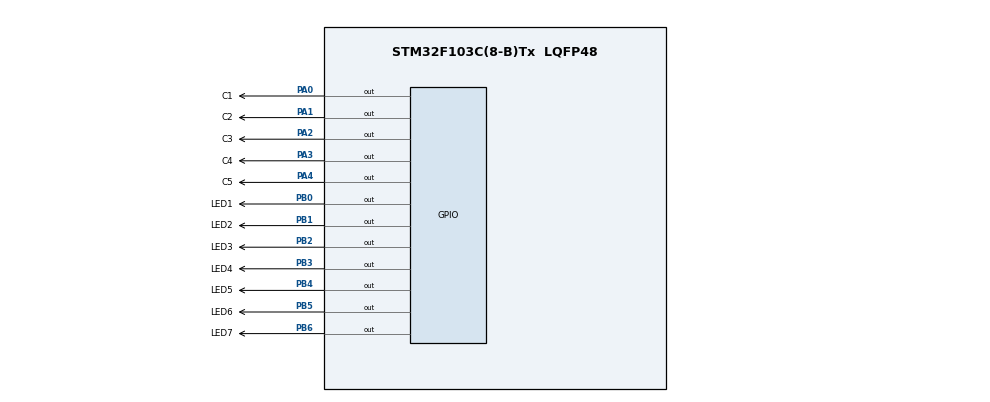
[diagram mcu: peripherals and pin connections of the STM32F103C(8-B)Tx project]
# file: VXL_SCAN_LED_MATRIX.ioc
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Mcu.Family=STM32F1
Mcu.Name=STM32F103C(8-B)Tx
Mcu.Package=LQFP48
NVIC.PriorityGroup=NVIC_PRIORITYGROUP_4
PA0-WKUP.GPIO_Label=C1
PA0-WKUP.Signal=GPIO_Output
PA1.GPIO_Label=C2
PA1.Signal=GPIO_Output
PA13.Mode=Serial_Wire
PA13.Signal=SYS_JTMS-SWDIO
PA14.Mode=Serial_Wire
PA14.Signal=SYS_JTCK-SWCLK
PA2.GPIO_Label=C3
PA2.Signal=GPIO_Output
PA3.GPIO_Label=C4
PA3.Signal=GPIO_Output
PA4.GPIO_Label=C5
PA4.Signal=GPIO_Output
PB0.GPIO_Label=LED1
PB0.Signal=GPIO_Output
PB1.GPIO_Label=LED2
PB1.Signal=GPIO_Output
PB2.GPIO_Label=LED3
PB2.Signal=GPIO_Output
PB3.GPIO_Label=LED4
PB3.Signal=GPIO_Output
PB4.GPIO_Label=LED5
PB4.Signal=GPIO_Output
PB5.GPIO_Label=LED6
PB5.Signal=GPIO_Output
PB6.GPIO_Label=LED7
PB6.Signal=GPIO_Output
ProjectManager.HeapSize=0x200
ProjectManager.StackSize=0x400
ProjectManager.TargetToolchain=MDK-ARM V5.27
RCC.APB1Freq_Value=8000000
RCC.APB2Freq_Value=8000000
board=custom

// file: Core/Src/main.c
/* USER CODE BEGIN Header */
/**
  ******************************************************************************
  * @file           : main.c
  * @brief          : Main program body
  ******************************************************************************
  * @attention
  *
  * Copyright (c) 2023 STMicroelectronics.
  * All rights reserved.
  *
  * This software is licensed under terms that can be found in the LICENSE file
  * in the root directory of this software component.
  * If no LICENSE file comes with this software, it is provided AS-IS.
  *
  ******************************************************************************
  */
/* USER CODE END Header */
#include "main.h"

/* USER CODE BEGIN PV */
const uint8_t NUMDATA[10][5] = {0x41,0x3a,0x36,0x2e,0x41,  //0      const nam trong ROM
																0x7f,0x5e,0x00,0x7e,0x7f,	 //1
																0x5e,0x3c,0x3a,0x36,0x4e,  //2
																0x3d,0x3e,0x2e,0x16,0x39,  //3
																0x73,0x6b,0x5b,0x00,0x7b,  //4
																0x0d,0x2e,0x2e,0x2e,0x31,  //5
																0x61,0x56,0x36,0x36,0x79,  //6
																0x3f,0x38,0x37,0x2f,0x1f,  //7
																0x49,0x36,0x36,0x36,0x49,  //8
																0x4f,0x36,0x36,0x35,0x43}; //9
/* USER CODE END PV */

void SystemClock_Config(void);
static void MX_GPIO_Init(void);

/* USER CODE BEGIN 0 */
void delay(unsigned int t)
{
	unsigned int x, y;
	for (x=0;x<t;x++)
	{
		for (y=0;y<123; y++);
	}
}
/* USER CODE END 0 */

int main(void)
{

  /* MCU Configuration--------------------------------------------------------*/

  /* Reset of all peripherals, Initializes the Flash interface and the Systick. */
  HAL_Init();

  /* Configure the system clock */
  SystemClock_Config();

  /* Initialize all configured peripherals */
  MX_GPIO_Init();

  /* Infinite loop */
  while (1)
  {
		for (uint8_t m = 0;m<10;m++)
		{
			for (uint8_t k = 0;k<20;k++) // tao do tre = delay
			{
				for (uint8_t n = 0;n<5;n++)
				{
					HAL_GPIO_WritePin(C1_GPIO_Port,C1_Pin,GPIO_PIN_RESET);
					HAL_GPIO_WritePin(C2_GPIO_Port,C2_Pin,GPIO_PIN_RESET);
					HAL_GPIO_WritePin(C3_GPIO_Port,C3_Pin,GPIO_PIN_RESET);
					HAL_GPIO_WritePin(C4_GPIO_Port,C4_Pin,GPIO_PIN_RESET);
					HAL_GPIO_WritePin(C5_GPIO_Port,C5_Pin,GPIO_PIN_RESET);

					// Chuan bi du lieu
					HAL_GPIO_WritePin(LED1_GPIO_Port,LED1_Pin,NUMDATA[m][n]&1);
					HAL_GPIO_WritePin(LED2_GPIO_Port,LED2_Pin,NUMDATA[m][n]&1<<1);
					HAL_GPIO_WritePin(LED3_GPIO_Port,LED3_Pin,NUMDATA[m][n]&1<<2);
					HAL_GPIO_WritePin(LED4_GPIO_Port,LED4_Pin,NUMDATA[m][n]&1<<3);
					HAL_GPIO_WritePin(LED5_GPIO_Port,LED5_Pin,NUMDATA[m][n]&1<<4);
					HAL_GPIO_WritePin(LED6_GPIO_Port,LED6_Pin,NUMDATA[m][n]&1<<5);
					HAL_GPIO_WritePin(LED7_GPIO_Port,LED7_Pin,NUMDATA[m][n]&1<<6);

					uint8_t col = 1<<n;
					HAL_GPIO_WritePin(C1_GPIO_Port,C1_Pin,col&1); // sang cot 1 khi n = 0
					HAL_GPIO_WritePin(C2_GPIO_Port,C2_Pin,col&1<<1); // sang cot 2 khi n = 1
					HAL_GPIO_WritePin(C3_GPIO_Port,C3_Pin,col&1<<2);
					HAL_GPIO_WritePin(C4_GPIO_Port,C4_Pin,col&1<<3);
					HAL_GPIO_WritePin(C5_GPIO_Port,C5_Pin,col&1<<4);
					HAL_Delay(1); // < 8.4ms
				}
			}
		}
		HAL_Delay(1);

  }
}

void SystemClock_Config(void)
{
  RCC_OscInitTypeDef RCC_OscInitStruct = {0};
  RCC_ClkInitTypeDef RCC_ClkInitStruct = {0};

  /** Initializes the RCC Oscillators according to the specified parameters
  * in the RCC_OscInitTypeDef structure.
  */
  RCC_OscInitStruct.OscillatorType = RCC_OSCILLATORTYPE_HSI;
  RCC_OscInitStruct.HSIState = RCC_HSI_ON;
  RCC_OscInitStruct.HSICalibrationValue = RCC_HSICALIBRATION_DEFAULT;
  RCC_OscInitStruct.PLL.PLLState = RCC_PLL_NONE;
  if (HAL_RCC_OscConfig(&RCC_OscInitStruct) != HAL_OK)
  {
    Error_Handler();
  }

  /** Initializes the CPU, AHB and APB buses clocks
  */
  RCC_ClkInitStruct.ClockType = RCC_CLOCKTYPE_HCLK|RCC_CLOCKTYPE_SYSCLK
                              |RCC_CLOCKTYPE_PCLK1|RCC_CLOCKTYPE_PCLK2;
  RCC_ClkInitStruct.SYSCLKSource = RCC_SYSCLKSOURCE_HSI;
  RCC_ClkInitStruct.AHBCLKDivider = RCC_SYSCLK_DIV1;
  RCC_ClkInitStruct.APB1CLKDivider = RCC_HCLK_DIV1;
  RCC_ClkInitStruct.APB2CLKDivider = RCC_HCLK_DIV1;

  if (HAL_RCC_ClockConfig(&RCC_ClkInitStruct, FLASH_LATENCY_0) != HAL_OK)
  {
    Error_Handler();
  }
}

static void MX_GPIO_Init(void)
{
  GPIO_InitTypeDef GPIO_InitStruct = {0};

  /* GPIO Ports Clock Enable */
  __HAL_RCC_GPIOA_CLK_ENABLE();
  __HAL_RCC_GPIOB_CLK_ENABLE();

  /*Configure GPIO pin Output Level */
  HAL_GPIO_WritePin(GPIOA, C1_Pin|C2_Pin|C3_Pin|C4_Pin
                          |C5_Pin, GPIO_PIN_RESET);

  /*Configure GPIO pin Output Level */
  HAL_GPIO_WritePin(GPIOB, LED1_Pin|LED2_Pin|LED3_Pin|LED4_Pin
                          |LED5_Pin|LED6_Pin|LED7_Pin, GPIO_PIN_RESET);

  /*Configure GPIO pins : C1_Pin C2_Pin C3_Pin C4_Pin
                           C5_Pin */
  GPIO_InitStruct.Pin = C1_Pin|C2_Pin|C3_Pin|C4_Pin
                          |C5_Pin;
  GPIO_InitStruct.Mode = GPIO_MODE_OUTPUT_PP;
  GPIO_InitStruct.Pull = GPIO_NOPULL;
  GPIO_InitStruct.Speed = GPIO_SPEED_FREQ_LOW;
  HAL_GPIO_Init(GPIOA, &GPIO_InitStruct);

  /*Configure GPIO pins : LED1_Pin LED2_Pin LED3_Pin LED4_Pin
                           LED5_Pin LED6_Pin LED7_Pin */
  GPIO_InitStruct.Pin = LED1_Pin|LED2_Pin|LED3_Pin|LED4_Pin
                          |LED5_Pin|LED6_Pin|LED7_Pin;
  GPIO_InitStruct.Mode = GPIO_MODE_OUTPUT_PP;
  GPIO_InitStruct.Pull = GPIO_NOPULL;
  GPIO_InitStruct.Speed = GPIO_SPEED_FREQ_LOW;
  HAL_GPIO_Init(GPIOB, &GPIO_InitStruct);

}

void Error_Handler(void)
{
  __disable_irq();
  while (1)
  {
  }
}
